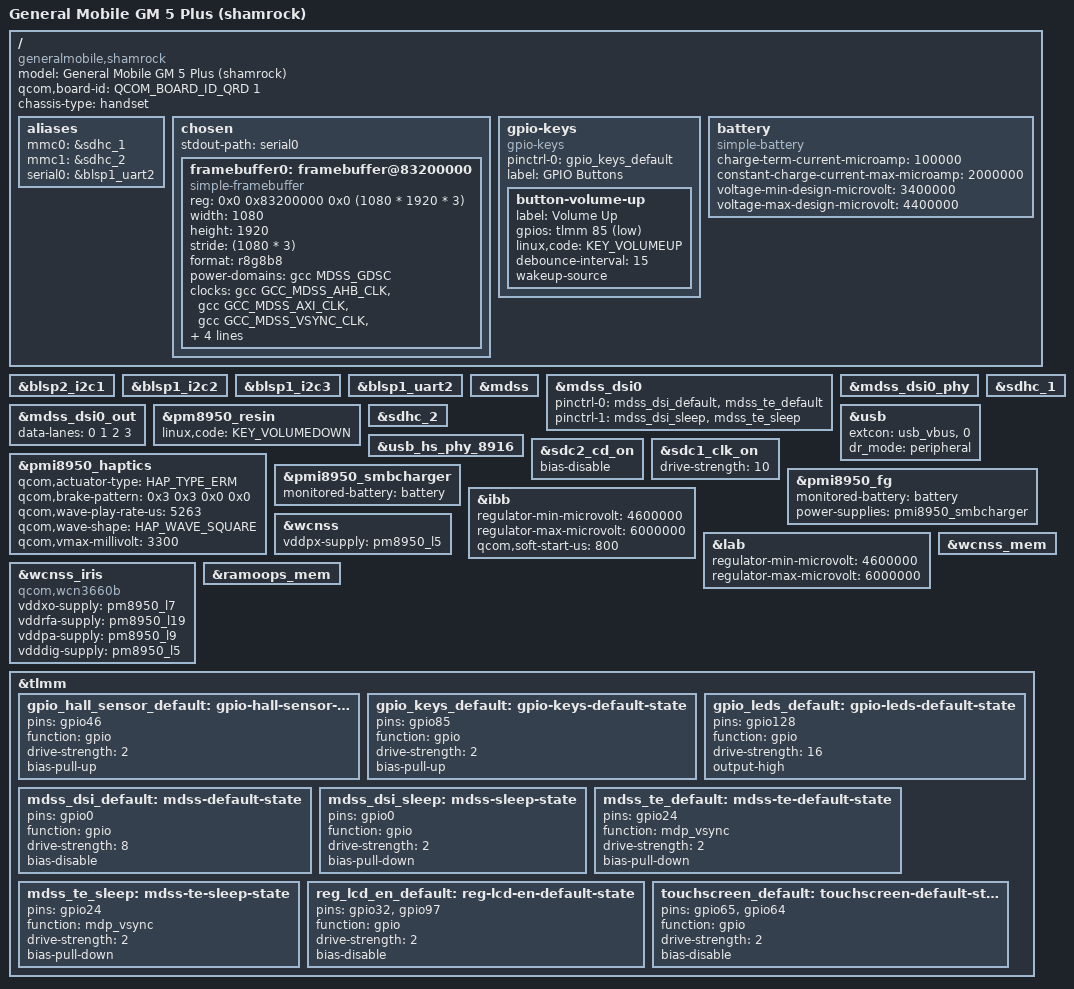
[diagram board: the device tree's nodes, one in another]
// SPDX-License-Identifier: GPL-2.0-only

/dts-v1/;

#include "msm8952-pm8950.dtsi"
#include "pmi8950.dtsi"
#include <dt-bindings/gpio/gpio.h>
#include <dt-bindings/leds/common.h>

/ {
	model = "General Mobile GM 5 Plus (shamrock)";
	compatible = "generalmobile,shamrock", "qcom,msm8952";
	qcom,board-id = <QCOM_BOARD_ID_QRD 1>;
	chassis-type = "handset";

	aliases {
		mmc0 = &sdhc_1; /* SDC1 eMMC slot */
		mmc1 = &sdhc_2; /* SDC2 SD card slot */
		serial0 = &blsp1_uart2;
	};

	chosen {
		stdout-path = "serial0";

		#address-cells = <2>;
		#size-cells = <2>;
		ranges;

		framebuffer0: framebuffer@83200000 {
			compatible = "simple-framebuffer";
			reg = <0x0 0x83200000 0x0 (1080 * 1920 * 3)>;
			width = <1080>;
			height = <1920>;
			stride = <(1080 * 3)>;
			format = "r8g8b8";

			power-domains = <&gcc MDSS_GDSC>;

			clocks = <&gcc GCC_MDSS_AHB_CLK>,
			         <&gcc GCC_MDSS_AXI_CLK>,
			         <&gcc GCC_MDSS_VSYNC_CLK>,
			         <&gcc GCC_MDSS_MDP_CLK>,
			         <&gcc GCC_MDSS_BYTE0_CLK>,
			         <&gcc GCC_MDSS_PCLK0_CLK>,
			         <&gcc GCC_MDSS_ESC0_CLK>;
		};
	};

	gpio-keys {
		compatible = "gpio-keys";

		pinctrl-0 = <&gpio_keys_default>;
		pinctrl-names = "default";

		label = "GPIO Buttons";

		button-volume-up {
			label = "Volume Up";
			gpios = <&tlmm 85 GPIO_ACTIVE_LOW>;
			linux,code = <KEY_VOLUMEUP>;
			debounce-interval = <15>;
			wakeup-source;
		};
	};

	battery: battery {
		compatible = "simple-battery";

		charge-term-current-microamp = <100000>;
		constant-charge-current-max-microamp = <2000000>; // it should be 3000000, but i am currently scared of burning battery
		voltage-min-design-microvolt = <3400000>;
		voltage-max-design-microvolt = <4400000>;
	};
};

&blsp2_i2c1 {
//	status = "okay";

//	amp@60 {
//		compatible = "ti,tpa6130a2";
//		pinctrl-names = "default", "sleep";
//		pinctrl-0 = <&tpa6130a2_active>;
//		pinctrl-1 = <&tpa6130a2_suspend>;
//		reg = <0x60>;
//		power-gpio = <&tlmm 61 GPIO_ACTIVE_HIGH>;
//		Vdd-supply = <&pm8950_l22>;
//	};

//	led-controller@68 { // TODO: Need to check current and regulator values from downstream
//		compatible = "si-en,sn3193";
//		reg = <0x68>;
//
//		shutdown-gpios = <&tlmm 68 GPIO_ACTIVE_HIGH>;
//
//		#address-cells = <1>;
//		#size-cells = <0>;
//
//		led@1 {
//			reg = <1>;
//			label = "red:status";
//			led-max-microamp = <17500>;
//		};
//
//		led@2 {
//			reg = <2>;
//			label = "green:status";
//			led-max-microamp = <17500>;
//		};
//
//		led@3 {
//			reg = <3>;
//			label = "blue:status";
//			led-max-microamp = <17500>;
//		};
//	};

//	tusb320@67 {
//		compatible = "ti,tusb320";
//		reg = <0x67>;
//		interrupt-parent = <&tlmm>;
//		interrupts = <45 IRQ_TYPE_EDGE_RISING>;
//	};
};

&blsp1_i2c2 {
//	status = "okay";
	/* SMB1351 charger */
};

&blsp1_i2c3 {
//	status = "okay";
};

&blsp1_uart2 {
//	status = "okay";
};

//&gpu {
//	status = "okay";
//};

&mdss {
//	status = "okay";
};

&mdss_dsi0 {
	pinctrl-names = "default", "sleep";
	pinctrl-0 = <&mdss_dsi_default &mdss_te_default>;
	pinctrl-1 = <&mdss_dsi_sleep &mdss_te_sleep>;
//	status = "okay";

//	panel@0 {
//		compatible = "dijing,otm1901a";
//		reg = <0>;
//
//		vsp-supply = <&lab>;
//		vsn-supply = <&ibb>;
//		reset-gpios = <&tlmm 0 GPIO_ACTIVE_LOW>;
//
//		port {
//			panel_in: endpoint {
//				remote-endpoint = <&mdss_dsi0_out>;
//			};
//		};
//	};
};

&mdss_dsi0_phy {
//	status = "okay";
};

&mdss_dsi0_out {
	data-lanes = <0 1 2 3>;
//	remote-endpoint = <&panel_in>;
};

&pm8950_resin {
	linux,code = <KEY_VOLUMEDOWN>;
	status = "okay";
};

&sdhc_1 {
	status = "okay";
};

&sdhc_2 {
	status = "okay";
};

&usb {
	extcon = <&usb_vbus>, <0>;
//	vbus-supply = <&otg_vbus>;
	dr_mode = "peripheral";
	status = "okay";
};

&usb_hs_phy_8916 {
	status = "okay";
};

&sdc2_cd_on {
	/delete-property/ bias-pull-up;
	bias-disable;
};

&sdc1_clk_on {
	drive-strength = <10>;
};

&pmi8950_haptics {
	qcom,actuator-type = <HAP_TYPE_ERM>;
	qcom,brake-pattern = <0x3 0x3 0x0 0x0>;
	qcom,wave-play-rate-us = <5263>;
	qcom,wave-shape = <HAP_WAVE_SQUARE>;
	qcom,vmax-millivolt = <3300>;

	status = "okay";
};

&pmi8950_smbcharger {
	monitored-battery = <&battery>;
	status = "okay";
};

&pmi8950_fg {
	monitored-battery = <&battery>;
	power-supplies = <&pmi8950_smbcharger>;
	status = "okay";
};

&ibb {
	regulator-min-microvolt = <4600000>;
	regulator-max-microvolt = <6000000>;
	qcom,soft-start-us = <800>;
};

&lab {
	regulator-min-microvolt = <4600000>;
	regulator-max-microvolt = <6000000>;
};

&wcnss {
	vddpx-supply = <&pm8950_l5>;
	status = "okay";
};

&wcnss_iris {
	compatible = "qcom,wcn3660b";
	vddxo-supply = <&pm8950_l7>;
	vddrfa-supply = <&pm8950_l19>;
	vddpa-supply = <&pm8950_l9>;
	vdddig-supply = <&pm8950_l5>;
};

&wcnss_mem {
	status = "okay";
};

&ramoops_mem {
	status = "okay";
};

&tlmm {
	gpio_hall_sensor_default: gpio-hall-sensor-default-state {
		pins = "gpio46";
		function = "gpio";
		drive-strength = <2>;
		bias-pull-up;
	};

	gpio_keys_default: gpio-keys-default-state {
		pins = "gpio85";
		function = "gpio";
		drive-strength = <2>;
		bias-pull-up;
	};

	gpio_leds_default: gpio-leds-default-state {
		pins = "gpio128";
		function = "gpio";
		drive-strength = <16>;
		output-high;
	};

	mdss_dsi_default: mdss-default-state {
		pins = "gpio0";
		function = "gpio";
		drive-strength = <8>;
		bias-disable;
	};

	mdss_dsi_sleep: mdss-sleep-state {
		pins = "gpio0";
		function = "gpio";
		drive-strength = <2>;
		bias-pull-down;
	};

	mdss_te_default: mdss-te-default-state {
		pins = "gpio24";
		function = "mdp_vsync";
		drive-strength = <2>;
		bias-pull-down;
	};

	mdss_te_sleep: mdss-te-sleep-state {
		pins = "gpio24";
		function = "mdp_vsync";
		drive-strength = <2>;
		bias-pull-down;
	};

	reg_lcd_en_default: reg-lcd-en-default-state {
		pins = "gpio32", "gpio97";
		function = "gpio";
		drive-strength = <2>;
		bias-disable;
	};

	touchscreen_default: touchscreen-default-state {
		pins = "gpio65", "gpio64";
		function = "gpio";
		drive-strength = <2>;
		bias-disable;
	};

//	tpa6130a2_active: tpa6130a2_active {
//		pins = "gpio61";
//		function = "gpio";
//		drive-strength = <8>;
//		bias-pull-down;
//		output-low;
//	};
//
//	tpa6130a2_suspend: tpa6130a2_suspend {
//		pins = "gpio61";
//		function = "gpio";
//		drive-strength = <2>;
//		bias-disable;
//	};
};

